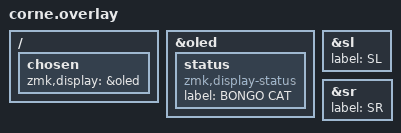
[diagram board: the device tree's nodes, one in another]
/ {
    chosen {
        zmk,display = &oled;
    };
};

&oled {
    status {
        compatible = "zmk,display-status";
        label = "BONGO CAT";
    };
};

&sl {
    label = "SL";
};

&sr {
    label = "SR";
}; 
